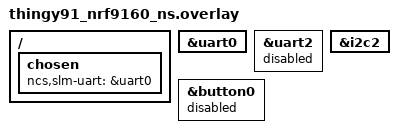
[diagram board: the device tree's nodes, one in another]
/*
 * Copyright (c) 2021 Nordic Semiconductor ASA
 *
 * SPDX-License-Identifier: LicenseRef-Nordic-5-Clause
 */

/ {
	chosen {
		ncs,slm-uart = &uart0;
	};
};

&uart0 {
	status = "okay";
};

&uart2 {
	status="disabled";
};

&i2c2 {
	status = "okay";
};

&button0 {
	status = "disabled";
};
